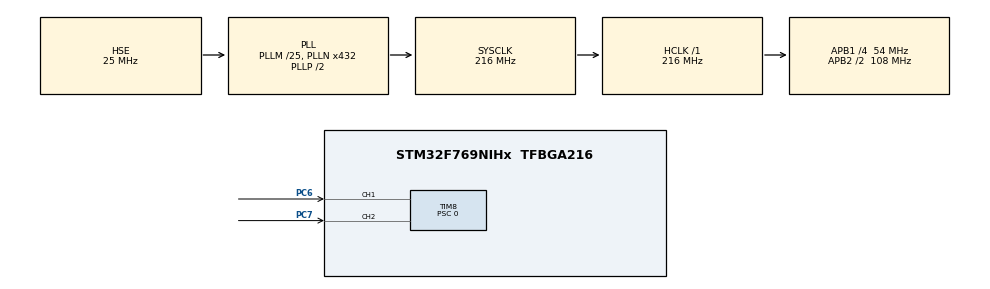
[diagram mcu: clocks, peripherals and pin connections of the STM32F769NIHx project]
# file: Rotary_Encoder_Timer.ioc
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Mcu.Family=STM32F7
Mcu.Name=STM32F769NIHx
Mcu.Package=TFBGA216
NVIC.PriorityGroup=NVIC_PRIORITYGROUP_4
PA13.Mode=Trace_Asynchronous_SW
PA13.Signal=SYS_JTMS-SWDIO
PA14.Mode=Trace_Asynchronous_SW
PA14.Signal=SYS_JTCK-SWCLK
PB3.Mode=Trace_Asynchronous_SW
PB3.Signal=SYS_JTDO-SWO
PC6.GPIO_ModeDefaultPP=GPIO_MODE_AF_PP
PC6.GPIO_PuPd=GPIO_PULLUP
PC6.GPIO_Speed=GPIO_SPEED_FREQ_VERY_HIGH
PC6.Signal=S_TIM8_CH1
PC7.GPIO_ModeDefaultPP=GPIO_MODE_AF_PP
PC7.GPIO_PuPd=GPIO_PULLUP
PC7.GPIO_Speed=GPIO_SPEED_FREQ_VERY_HIGH
PC7.Signal=S_TIM8_CH2
PH0/OSC_IN.Mode=HSE-External-Oscillator
PH0/OSC_IN.Signal=RCC_OSC_IN
PH1/OSC_OUT.Mode=HSE-External-Oscillator
PH1/OSC_OUT.Signal=RCC_OSC_OUT
ProjectManager.HeapSize=0x200
ProjectManager.StackSize=0x400
ProjectManager.TargetToolchain=TrueSTUDIO
RCC.AHBFreq_Value=216000000
RCC.APB1CLKDivider=RCC_HCLK_DIV4
RCC.APB1Freq_Value=54000000
RCC.APB1TimFreq_Value=108000000
RCC.APB2CLKDivider=RCC_HCLK_DIV2
RCC.APB2Freq_Value=108000000
RCC.APB2TimFreq_Value=216000000
RCC.CortexFreq_Value=216000000
RCC.EnbaleCSS=true
RCC.HCLKFreq_Value=216000000
RCC.HSE_VALUE=25000000
RCC.HSI_VALUE=16000000
RCC.LSE_VALUE=32768
RCC.PLLM=25
RCC.PLLN=432
RCC.PLLSourceVirtual=RCC_PLLSOURCE_HSE
RCC.SYSCLKFreq_VALUE=216000000
RCC.SYSCLKSource=RCC_SYSCLKSOURCE_PLLCLK
RCC.USBFreq_Value=216000000
RCC.VCOOutputFreq_Value=432000000
SH.S_TIM8_CH1.0=TIM8_CH1,Encoder_Interface
SH.S_TIM8_CH2.0=TIM8_CH2,Encoder_Interface
TIM8.ClockDivision=TIM_CLOCKDIVISION_DIV1
TIM8.EncoderMode=TIM_ENCODERMODE_TI12
TIM8.IC1Filter=10
TIM8.IC1Prescaler=TIM_ICPSC_DIV1
TIM8.IC2Filter=10
TIM8.IC2Prescaler=TIM_ICPSC_DIV1
TIM8.Period=65535
TIM8.Prescaler=0
board=custom

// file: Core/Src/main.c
/* USER CODE BEGIN Header */
/**
 ******************************************************************************
 * @file           : main.c
 * @brief          : Main program body
 ******************************************************************************
 * @attention
 *
 * <h2><center>&copy; Copyright (c) 2019 STMicroelectronics.
 * All rights reserved.</center></h2>
 *
 * This software component is licensed by ST under BSD 3-Clause license,
 * the "License"; You may not use this file except in compliance with the
 * License. You may obtain a copy of the License at:
 *                        opensource.org/licenses/BSD-3-Clause
 *
 ******************************************************************************
 */
/* USER CODE END Header */

#include "main.h"
#include "tim.h"
#include "gpio.h"

void SystemClock_Config(void);

/* USER CODE BEGIN 0 */
static volatile uint32_t direction = 0;
static volatile uint32_t counter = 0;
/* USER CODE END 0 */

int main(void)
{

	/* MCU Configuration--------------------------------------------------------*/

	/* Reset of all peripherals, Initializes the Flash interface and the Systick. */
	HAL_Init();

	/* Configure the system clock */
	SystemClock_Config();

	/* Initialize all configured peripherals */
	MX_GPIO_Init();
	MX_TIM8_Init();
	/* USER CODE BEGIN 2 */
	HAL_TIM_Encoder_Start(&htim8, TIM_CHANNEL_ALL);
	/* USER CODE END 2 */

	/* Infinite loop */
	/* USER CODE BEGIN WHILE */
	while (1)
	{
		direction = __HAL_TIM_IS_TIM_COUNTING_DOWN(&htim8);
		counter = __HAL_TIM_GET_COUNTER(&htim8);

		HAL_GPIO_TogglePin(GPIOJ, GPIO_PIN_13);
		HAL_Delay(50);
		/* USER CODE END WHILE */

	}
}

void SystemClock_Config(void)
{
	RCC_OscInitTypeDef RCC_OscInitStruct = {0};
	RCC_ClkInitTypeDef RCC_ClkInitStruct = {0};

	/** Configure the main internal regulator output voltage
	 */
	__HAL_RCC_PWR_CLK_ENABLE();
	__HAL_PWR_VOLTAGESCALING_CONFIG(PWR_REGULATOR_VOLTAGE_SCALE1);
	/** Initializes the CPU, AHB and APB busses clocks
	 */
	RCC_OscInitStruct.OscillatorType = RCC_OSCILLATORTYPE_HSE;
	RCC_OscInitStruct.HSEState = RCC_HSE_ON;
	RCC_OscInitStruct.PLL.PLLState = RCC_PLL_ON;
	RCC_OscInitStruct.PLL.PLLSource = RCC_PLLSOURCE_HSE;
	RCC_OscInitStruct.PLL.PLLM = 25;
	RCC_OscInitStruct.PLL.PLLN = 432;
	RCC_OscInitStruct.PLL.PLLP = RCC_PLLP_DIV2;
	RCC_OscInitStruct.PLL.PLLQ = 2;
	if (HAL_RCC_OscConfig(&RCC_OscInitStruct) != HAL_OK)
	{
		Error_Handler();
	}
	/** Activate the Over-Drive mode
	 */
	if (HAL_PWREx_EnableOverDrive() != HAL_OK)
	{
		Error_Handler();
	}
	/** Initializes the CPU, AHB and APB busses clocks
	 */
	RCC_ClkInitStruct.ClockType = RCC_CLOCKTYPE_HCLK|RCC_CLOCKTYPE_SYSCLK
			|RCC_CLOCKTYPE_PCLK1|RCC_CLOCKTYPE_PCLK2;
	RCC_ClkInitStruct.SYSCLKSource = RCC_SYSCLKSOURCE_PLLCLK;
	RCC_ClkInitStruct.AHBCLKDivider = RCC_SYSCLK_DIV1;
	RCC_ClkInitStruct.APB1CLKDivider = RCC_HCLK_DIV4;
	RCC_ClkInitStruct.APB2CLKDivider = RCC_HCLK_DIV2;

	if (HAL_RCC_ClockConfig(&RCC_ClkInitStruct, FLASH_LATENCY_7) != HAL_OK)
	{
		Error_Handler();
	}
	/** Enables the Clock Security System
	 */
	HAL_RCC_EnableCSS();
}

void Error_Handler(void)
{
}

/************************ (C) COPYRIGHT STMicroelectronics *****END OF FILE****/
